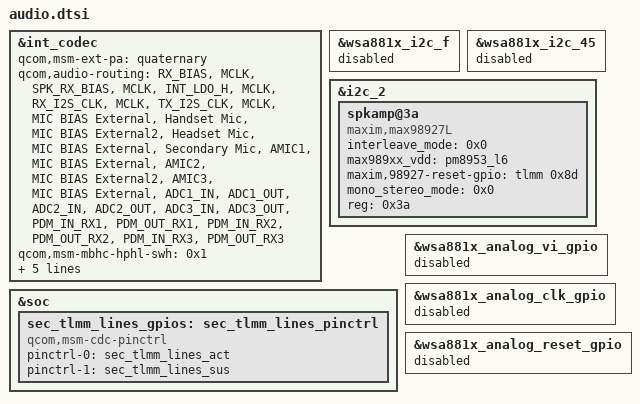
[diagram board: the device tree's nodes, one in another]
/* msm-audio.dtsi */
&int_codec {
	qcom,msm-ext-pa = "quaternary";
	qcom,audio-routing =
			"RX_BIAS", "MCLK",
			"SPK_RX_BIAS", "MCLK",
			"INT_LDO_H", "MCLK",
			"RX_I2S_CLK", "MCLK",
			"TX_I2S_CLK", "MCLK",
			"MIC BIAS External", "Handset Mic",
			"MIC BIAS External2", "Headset Mic",
			"MIC BIAS External", "Secondary Mic",
			"AMIC1", "MIC BIAS External",
			"AMIC2", "MIC BIAS External2",
			"AMIC3", "MIC BIAS External",
			"ADC1_IN", "ADC1_OUT",
			"ADC2_IN", "ADC2_OUT",
			"ADC3_IN", "ADC3_OUT",
			"PDM_IN_RX1", "PDM_OUT_RX1",
			"PDM_IN_RX2", "PDM_OUT_RX2",
			"PDM_IN_RX3", "PDM_OUT_RX3";
};

/* msm8953-audio.dtsi */
&int_codec {
	/delete-property/ qcom,cdc-us-euro-gpios;
	qcom,msm-mbhc-hphl-swh = <0x1>;
	qcom,msm-mbhc-gnd-swh = <0x1>;
	qcom,msm-micbias2-ext-cap;

	/delete-property/ asoc-wsa-codec-names;
	/delete-property/ asoc-wsa-codec-prefixes;
};

/* msm8953-audio-mtp.dtsi */
&int_codec {
	qcom,model = "msm8952-snd-card-mtp";
	qcom,msm-hs-micbias-type = "external";
};

&wsa881x_i2c_f {
	status = "disabled";
};

&wsa881x_i2c_45 {
	status = "disabled";
};

/* MAX98927 codec */
&i2c_2 {
	spkamp@3a {
		compatible = "maxim,max98927L";
		interleave_mode = <0x0>;
		max989xx_vdd = <&pm8953_l6>;
		maxim,98927-reset-gpio = <&tlmm 0x8d 0x0>;
		mono_stereo_mode = <0x0>;
		reg = <0x3a>;
		status = "okay";
	};
};

/* GPIOs */
&soc {
	sec_tlmm_lines_gpios: sec_tlmm_lines_pinctrl {
		compatible = "qcom,msm-cdc-pinctrl";
		pinctrl-names = "aud_active", "aud_sleep";
		pinctrl-0 = <&sec_tlmm_lines_act>;
		pinctrl-1 = <&sec_tlmm_lines_sus>;
	};
};

&int_codec {
	qcom,cdc-ext-pa-gpios = <&sec_tlmm_lines_gpios>;
};

/* Disable unused wsa881x i2c nodes */
&wsa881x_i2c_f {
        status = "disabled";
};

&wsa881x_i2c_45 {
        status = "disabled";
};

&wsa881x_analog_vi_gpio {
        status = "disabled";
};

&wsa881x_analog_clk_gpio {
        status = "disabled";
};

&wsa881x_analog_reset_gpio {
        status = "disabled";
};
